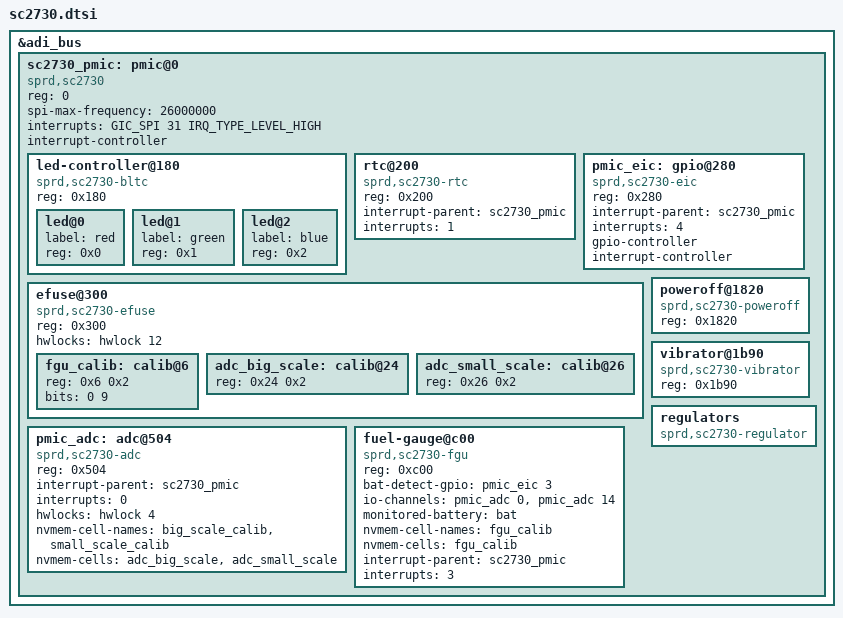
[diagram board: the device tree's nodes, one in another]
// SPDX-License-Identifier: (GPL-2.0+ OR MIT)
/*
 * Spreadtrum SC2730 PMIC dts file
 *
 * Copyright (C) 2018, Spreadtrum Communications Inc.
 */

&adi_bus {
	sc2730_pmic: pmic@0 {
		compatible = "sprd,sc2730";
		reg = <0>;
		spi-max-frequency = <26000000>;
		interrupts = <GIC_SPI 31 IRQ_TYPE_LEVEL_HIGH>;
		interrupt-controller;
		#interrupt-cells = <1>;
		#address-cells = <1>;
		#size-cells = <0>;

		led-controller@180 {
			compatible = "sprd,sc2730-bltc", "sprd,sc2731-bltc";
			reg = <0x180>;
			#address-cells = <1>;
			#size-cells = <0>;

			led@0 {
				label = "red";
				reg = <0x0>;
			};

			led@1 {
				label = "green";
				reg = <0x1>;
			};

			led@2 {
				label = "blue";
				reg = <0x2>;
			};
		};

		rtc@200 {
			compatible = "sprd,sc2730-rtc", "sprd,sc2731-rtc";
			reg = <0x200>;
			interrupt-parent = <&sc2730_pmic>;
			interrupts = <1>;
		};

		pmic_eic: gpio@280 {
			compatible = "sprd,sc2730-eic", "sprd,sc2731-eic";
			reg = <0x280>;
			interrupt-parent = <&sc2730_pmic>;
			interrupts = <4>;
			gpio-controller;
			#gpio-cells = <2>;
			interrupt-controller;
			#interrupt-cells = <2>;
		};

		efuse@300 {
			compatible = "sprd,sc2730-efuse";
			reg = <0x300>;
			#address-cells = <1>;
			#size-cells = <1>;
			hwlocks = <&hwlock 12>;

			fgu_calib: calib@6 {
				reg = <0x6 0x2>;
				bits = <0 9>;
			};

			adc_big_scale: calib@24 {
				reg = <0x24 0x2>;
			};

			adc_small_scale: calib@26 {
				reg = <0x26 0x2>;
			};
		};

		pmic_adc: adc@504 {
			compatible = "sprd,sc2730-adc";
			reg = <0x504>;
			interrupt-parent = <&sc2730_pmic>;
			interrupts = <0>;
			#io-channel-cells = <1>;
			hwlocks = <&hwlock 4>;
			nvmem-cell-names = "big_scale_calib", "small_scale_calib";
			nvmem-cells = <&adc_big_scale>, <&adc_small_scale>;
		};

		fuel-gauge@c00 {
			compatible = "sprd,sc2730-fgu";
			reg = <0xc00>;
			bat-detect-gpio = <&pmic_eic 3 GPIO_ACTIVE_HIGH>;
			io-channels = <&pmic_adc 0>, <&pmic_adc 14>;
			io-channel-names = "bat-temp", "charge-vol";
			monitored-battery = <&bat>;
			nvmem-cell-names = "fgu_calib";
			nvmem-cells = <&fgu_calib>;
			interrupt-parent = <&sc2730_pmic>;
			interrupts = <3>;
		};

		poweroff@1820 {
			compatible = "sprd,sc2730-poweroff";
			reg = <0x1820>;
		};

		vibrator@1b90 {
			compatible = "sprd,sc2730-vibrator";
			reg = <0x1b90>;
		};

		regulators {
			compatible = "sprd,sc2730-regulator";
		};
	};
};
